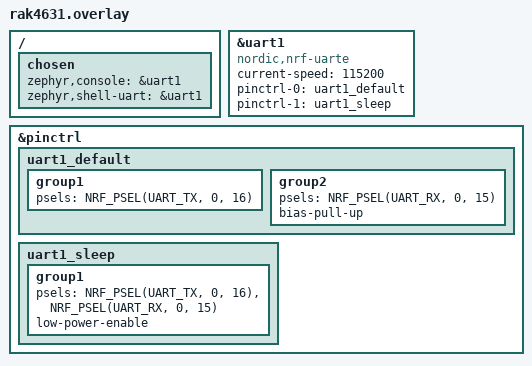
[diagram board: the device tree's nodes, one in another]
/*
 * HW Test - Power & Buzzer - RAK4631 Overlay
 * Debug UART: TX=P0.16, RX=P0.15
 */

/ {
	chosen {
		zephyr,console = &uart1;
		zephyr,shell-uart = &uart1;
	};
};

&uart1 {
	compatible = "nordic,nrf-uarte";
	status = "okay";
	current-speed = <115200>;
	pinctrl-0 = <&uart1_default>;
	pinctrl-1 = <&uart1_sleep>;
	pinctrl-names = "default", "sleep";
};

&pinctrl {
	uart1_default: uart1_default {
		group1 {
			psels = <NRF_PSEL(UART_TX, 0, 16)>;
		};
		group2 {
			psels = <NRF_PSEL(UART_RX, 0, 15)>;
			bias-pull-up;
		};
	};

	uart1_sleep: uart1_sleep {
		group1 {
			psels = <NRF_PSEL(UART_TX, 0, 16)>,
				<NRF_PSEL(UART_RX, 0, 15)>;
			low-power-enable;
		};
	};
};
